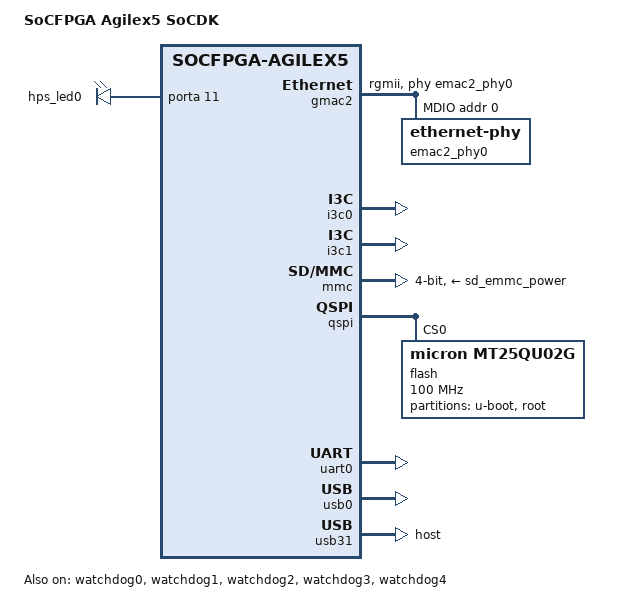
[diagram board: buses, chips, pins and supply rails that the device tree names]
// SPDX-License-Identifier: GPL-2.0-only
/*
 * Copyright (C) 2023, Intel Corporation
 */
#include "socfpga_agilex5.dtsi"

/ {
	model = "SoCFPGA Agilex5 SoCDK";
	compatible = "intel,socfpga-agilex5-socdk", "intel,socfpga-agilex5";

	aliases {
		serial0 = &uart0;
		ethernet0 = &gmac0;
		ethernet1 = &gmac1;
		ethernet2 = &gmac2;
	};

	chosen {
		stdout-path = "serial0:115200n8";
		bootargs = "console=uart8250,mmio32,0x10c02000,115200n8 \
			root=/dev/ram0 rw initrd=0x10000000 init=/sbin/init \
			ramdisk_size=10000000 earlycon=uart8250,mmio32,0x10c02000,115200n8 \
			panic=-1 rootfstype=ext3";
	};

	leds {
		compatible = "gpio-leds";

		led-0 {
			label = "hps_led0";
			gpios = <&porta 11 GPIO_ACTIVE_HIGH>;
		};

	};

	memory@80000000 {
		device_type = "memory";
		/* We expect the bootloader to fill in the reg */
		reg = <0x0 0x80000000 0x0 0x0>;
	};
};

&gpio0 {
	status = "okay";
};

&gmac1 {
	status = "disabled";
	phy-mode = "rgmii";
	mac-mode = "gmii";
	phy-handle = <&emac1_phy0>;

	max-frame-size = <9000>;

	mdio0 {
		#address-cells = <1>;
		#size-cells = <0>;
		compatible = "snps,dwmac-mdio";
		emac1_phy0: ethernet-phy@0 {
			reg = <0>;
		};
	};
};

&gmac2 {
	status = "okay";
	phy-mode = "rgmii";
	phy-handle = <&emac2_phy0>;
	max-frame-size = <9000>;

	mdio0 {
		#address-cells = <1>;
		#size-cells = <0>;
		compatible = "snps,dwmac-mdio";
		emac2_phy0: ethernet-phy@0 {
			reg = <0>;
		};
	};
};

&gpio1 {
	status = "okay";
};

&gmac0 {
	status = "disabled";
	phy-mode = "rgmii";
	phy-handle = <&emac0_phy0>;

	max-frame-size = <9000>;

	mdio0 {
		#address-cells = <1>;
		#size-cells = <0>;
		compatible = "snps,dwmac-mdio";
		emac0_phy0: ethernet-phy@0 {
			reg = <0>;
		};
	};
};

&i3c0 {
	status = "okay";
};

&i3c1 {
	status = "okay";
};

&sd_io_1v8_reg {
	gpios = <&portb 3 GPIO_ACTIVE_HIGH>;
};

&mmc {
	status = "okay";

	no-mmc;
	no-1-8-v;
	disable-wp;
	cap-sd-highspeed;
	bus-width = <4>;
	vmmc-supply = <&sd_emmc_power>;
	vqmmc-supply = <&sd_io_1v8_reg>;
	max-frequency = <200000000>;
	sdhci-caps = <0x00000000 0x0000c800>;
	sdhci-caps-mask = <0x00002007 0x0000ff00>;
};

&osc1 {
	clock-frequency = <25000000>;
};

&qspi {
	status = "okay";
	flash@0 {
		compatible = "micron,mt25qu02g", "jedec,spi-nor";
		reg = <0>;
		spi-max-frequency = <100000000>;
		m25p,fast-read;
		cdns,read-delay = <2>;
		cdns,tshsl-ns = <50>;
		cdns,tsd2d-ns = <50>;
		cdns,tchsh-ns = <4>;
		cdns,tslch-ns = <4>;
		spi-tx-bus-width = <4>;
		spi-rx-bus-width = <4>;

		partitions {
			compatible = "fixed-partitions";
			#address-cells = <1>;
			#size-cells = <1>;
			rsu-handle = <&qspi_boot>;

			qspi_boot: partition@0 {
				label = "u-boot";
				reg = <0x0 0x04200000>;
			};

			root: partition@4200000 {
				label = "root";
				reg = <0x04200000 0x0be00000>;
			};
		};
	};
};

&uart0 {
	status = "okay";
};

&usb0 {
	status = "okay";
	disable-over-current;
};

&usb31 {
	status = "okay";
	dr_mode = "host";
};

&smmu {
	status = "okay";
};

&watchdog0 {
	status = "okay";
};
&watchdog1 {
	status = "okay";
};
&watchdog2 {
	status = "okay";
};
&watchdog3 {
	status = "okay";
};
&watchdog4 {
	status = "okay";
	disable-over-current;
};

&temp_volt {
	voltage {
		#address-cells = <1>;
		#size-cells = <0>;
		input@2 {
			label = "0.8V VCC";
			reg = <2>;
		};

		input@3 {
			label = "1.8V VCCIO_SDM";
			reg = <3>;
		};

		input@4 {
			label = "1.8V VCCPT";
			reg = <4>;
		};

		input@5 {
			label = "1.2V VCCCRCORE";
			reg = <5>;
		};

		input@6 {
			label = "0.9V VCCH";
			reg = <6>;
		};

		input@7 {
			label = "0.8V VCCL";
			reg = <7>;
		};
	};

	temperature {
		#address-cells = <1>;
		#size-cells = <0>;

		input@0 {
			label = "Main Die SDM";
			reg = <0x0>;
		};

		input@10001 {
			label = "Main Die corner bottom left max";
			reg = <0x10000>;
		};

		input@30001 {
			label = "Main Die corner bottom right max";
			reg = <0x30000>;
		};

		input@40001 {
			label = "Main Die corner top right max";
			reg = <0x40000>;
		};
	};
};
